AUTOSAR XML (schema 4-0-3)
package /ComponentTypes
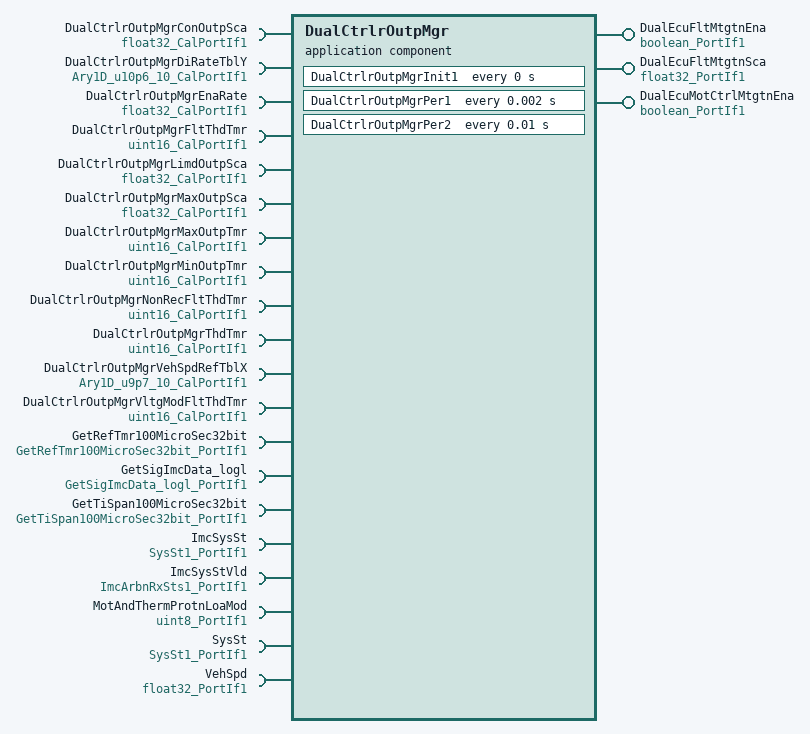
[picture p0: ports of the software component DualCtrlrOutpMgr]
  application sw component type DualCtrlrOutpMgr
    provide port DualEcuFltMtgtnEna: nonqueued-sender-com-spec{data-element=Logl, init-value=0}, provided-interface=boolean_PortIf1
    provide port DualEcuFltMtgtnSca: nonqueued-sender-com-spec{data-element=Val, init-value=0.5}, provided-interface=float32_PortIf1
    provide port DualEcuMotCtrlMtgtnEna: nonqueued-sender-com-spec{data-element=Logl, init-value=0}, provided-interface=boolean_PortIf1
    20 x require port:
      DualCtrlrOutpMgrConOutpSca: parameter-require-com-spec{init-value=0.5, parameter=Val}, required-interface=float32_CalPortIf1
      DualCtrlrOutpMgrDiRateTblY: parameter-require-com-spec{init-value=10 x 6400, parameter=Ary1D}, required-interface=Ary1D_u10p6_10_CalPortIf1
      DualCtrlrOutpMgrEnaRate: parameter-require-com-spec{init-value=100, parameter=Val}, required-interface=float32_CalPortIf1
      DualCtrlrOutpMgrFltThdTmr: parameter-require-com-spec{init-value=20, parameter=Val}, required-interface=uint16_CalPortIf1
      DualCtrlrOutpMgrLimdOutpSca: parameter-require-com-spec{init-value=0.3, parameter=Val}, required-interface=float32_CalPortIf1
      DualCtrlrOutpMgrMaxOutpSca: parameter-require-com-spec{init-value=1, parameter=Val}, required-interface=float32_CalPortIf1
      DualCtrlrOutpMgrMaxOutpTmr: parameter-require-com-spec{init-value=100, parameter=Val}, required-interface=uint16_CalPortIf1
      DualCtrlrOutpMgrMinOutpTmr: parameter-require-com-spec{init-value=100, parameter=Val}, required-interface=uint16_CalPortIf1
      DualCtrlrOutpMgrNonRecFltThdTmr: parameter-require-com-spec{init-value=30, parameter=Val}, required-interface=uint16_CalPortIf1
      DualCtrlrOutpMgrThdTmr: parameter-require-com-spec{init-value=20, parameter=Val}, required-interface=uint16_CalPortIf1
      DualCtrlrOutpMgrVehSpdRefTblX: parameter-require-com-spec{init-value=[0, 1920, 5120, 7680, 9600, 12800, 16000, 16640, 17920, 20480], parameter=Ary1D}, required-interface=Ary1D_u9p7_10_CalPortIf1
      DualCtrlrOutpMgrVltgModFltThdTmr: parameter-require-com-spec{init-value=20, parameter=Val}, required-interface=uint16_CalPortIf1
      GetRefTmr100MicroSec32bit: client-com-spec=Oper, required-interface=GetRefTmr100MicroSec32bit_PortIf1
      GetSigImcData_logl: client-com-spec=Oper, required-interface=GetSigImcData_logl_PortIf1
      GetTiSpan100MicroSec32bit: client-com-spec=Oper, required-interface=GetTiSpan100MicroSec32bit_PortIf1
      ImcSysSt: nonqueued-receiver-com-spec{data-element=Val, filter=data-filter-type=ALWAYS, init-value=3}, required-interface=SysSt1_PortIf1
      ImcSysStVld: nonqueued-receiver-com-spec{data-element=Val, filter=data-filter-type=ALWAYS, init-value=0}, required-interface=ImcArbnRxSts1_PortIf1
      MotAndThermProtnLoaMod: nonqueued-receiver-com-spec{data-element=Val, filter=data-filter-type=ALWAYS, init-value=0}, required-interface=uint8_PortIf1
      SysSt: nonqueued-receiver-com-spec{data-element=Val, filter=data-filter-type=ALWAYS, init-value=3}, required-interface=SysSt1_PortIf1
      VehSpd: nonqueued-receiver-com-spec{data-element=Val, filter=data-filter-type=ALWAYS, init-value=0}, required-interface=float32_PortIf1
    behavior DualCtrlrOutpMgr_InternalBehavior
      ar-typed-per-instance-memorys:
        16 x data, all with sw-calibration-access=READ-ONLY:
          FltLrngEnaPrev: type=boolean
          FltRefTiEnaLrng: type=uint32
          FltStsPrev: type=boolean
          LtchImcDualEcuMotCtrlMtgtnEnaPrev: type=boolean
          LtchRefTiEnaLrng: type=uint32
          LtchSysStPrev: type=boolean
          MaxOutpRefTiEna: type=uint32
          MaxOutpTmrCmpl: type=boolean
          NonRecFltEnaPrev: type=boolean
          NonRecFltRefTiEnaLrng: type=uint32
          OutpSca: type=float32
          PrevLtch: type=boolean
          PrevLtchNonRecFlt: type=boolean
          RefTiEnaLrng: type=uint32
          SysStLrngEnaPrev: type=boolean
          SysStRefTiEnaLrng: type=uint32
      timing event DualCtrlrOutpMgrInit1_InitEvent: start-on-event=DualCtrlrOutpMgrInit1, period=0
      timing event TMT_DualCtrlrOutpMgrPer1: start-on-event=DualCtrlrOutpMgrPer1, period=0.002
      timing event TMT_DualCtrlrOutpMgrPer2: start-on-event=DualCtrlrOutpMgrPer2, period=0.01
      explicit-inter-runnable-variables:
        4 x data, all with type=boolean, init-value=0:
          ImcDiagcStsNonRcvrlReqDiFltPrsnt
          ImcDiagcStsNonRcvrlReqDiFltPrsntVld
          ImcDualEcuMotCtrlMtgtnEna
          ImcDualEcuMotCtrlMtgtnEnaVld
      port-api-options:
        enable-take-address=false, indirect-api=false, port=DualCtrlrOutpMgrConOutpSca
        enable-take-address=false, indirect-api=false, port=DualCtrlrOutpMgrDiRateTblY
        enable-take-address=false, indirect-api=false, port=DualCtrlrOutpMgrEnaRate
        enable-take-address=false, indirect-api=false, port=DualCtrlrOutpMgrFltThdTmr
        enable-take-address=false, indirect-api=false, port=DualCtrlrOutpMgrLimdOutpSca
        enable-take-address=false, indirect-api=false, port=DualCtrlrOutpMgrMaxOutpSca
        enable-take-address=false, indirect-api=false, port=DualCtrlrOutpMgrMaxOutpTmr
        enable-take-address=false, indirect-api=false, port=DualCtrlrOutpMgrMinOutpTmr
        enable-take-address=false, indirect-api=false, port=DualCtrlrOutpMgrNonRecFltThdTmr
        enable-take-address=false, indirect-api=false, port=DualCtrlrOutpMgrThdTmr
        enable-take-address=false, indirect-api=false, port=DualCtrlrOutpMgrVehSpdRefTblX
        enable-take-address=false, indirect-api=false, port=DualCtrlrOutpMgrVltgModFltThdTmr
        enable-take-address=false, indirect-api=false, port=DualEcuFltMtgtnEna
        enable-take-address=false, indirect-api=false, port=DualEcuFltMtgtnSca
        enable-take-address=false, indirect-api=false, port=DualEcuMotCtrlMtgtnEna
        enable-take-address=false, indirect-api=false, port=GetRefTmr100MicroSec32bit
        enable-take-address=false, indirect-api=false, port=GetSigImcData_logl
        enable-take-address=false, indirect-api=false, port=GetTiSpan100MicroSec32bit
        enable-take-address=false, indirect-api=false, port=ImcSysSt
        enable-take-address=false, indirect-api=false, port=ImcSysStVld
        enable-take-address=false, indirect-api=false, port=MotAndThermProtnLoaMod
        enable-take-address=false, indirect-api=false, port=SysSt
        enable-take-address=false, indirect-api=false, port=VehSpd
      runnable DualCtrlrOutpMgrInit1
        sync call SC_GetRefTmr100MicroSec32bit_PortIf1_Oper: operation=GetRefTmr100MicroSec32bit.Oper, timeout=0
      runnable DualCtrlrOutpMgrPer1
        data-receive-point-by-arguments:
          5 x access:
            REC_ImcSysSt_Val: accessed-variable=ImcSysSt.Val
            REC_ImcSysStVld_Val: accessed-variable=ImcSysStVld.Val
            REC_MotAndThermProtnLoaMod_Val: accessed-variable=MotAndThermProtnLoaMod.Val
            REC_SysSt_Val: accessed-variable=SysSt.Val
            REC_VehSpd_Val: accessed-variable=VehSpd.Val
        data-send-points:
          access SEND_DualEcuFltMtgtnEna_Logl: accessed-variable=DualEcuFltMtgtnEna.Logl
          access SEND_DualEcuFltMtgtnSca_Val: accessed-variable=DualEcuFltMtgtnSca.Val
          access SEND_DualEcuMotCtrlMtgtnEna_Logl: accessed-variable=DualEcuMotCtrlMtgtnEna.Logl
        read-local-variables:
          4 x access:
            READ_ImcDiagcStsNonRcvrlReqDiFltPrsnt: accessed-variable=ImcDiagcStsNonRcvrlReqDiFltPrsnt
            READ_ImcDiagcStsNonRcvrlReqDiFltPrsntVld: accessed-variable=ImcDiagcStsNonRcvrlReqDiFltPrsntVld
            READ_ImcDualEcuMotCtrlMtgtnEna: accessed-variable=ImcDualEcuMotCtrlMtgtnEna
            READ_ImcDualEcuMotCtrlMtgtnEnaVld: accessed-variable=ImcDualEcuMotCtrlMtgtnEnaVld
        sync call SC_GetRefTmr100MicroSec32bit_PortIf1_Oper: operation=GetRefTmr100MicroSec32bit.Oper, timeout=0
        sync call SC_GetTiSpan100MicroSec32bit_PortIf1_Oper: operation=GetTiSpan100MicroSec32bit.Oper, timeout=0
      runnable DualCtrlrOutpMgrPer2
        sync call SC_GetSigImcData_logl_PortIf1_Oper: operation=GetSigImcData_logl.Oper, timeout=0
        written-local-variables:
          4 x access:
            WRITE_ImcDiagcStsNonRcvrlReqDiFltPrsnt: accessed-variable=ImcDiagcStsNonRcvrlReqDiFltPrsnt
            WRITE_ImcDiagcStsNonRcvrlReqDiFltPrsntVld: accessed-variable=ImcDiagcStsNonRcvrlReqDiFltPrsntVld
            WRITE_ImcDualEcuMotCtrlMtgtnEna: accessed-variable=ImcDualEcuMotCtrlMtgtnEna
            WRITE_ImcDualEcuMotCtrlMtgtnEnaVld: accessed-variable=ImcDualEcuMotCtrlMtgtnEnaVld
  swc implementation DualCtrlrOutpMgr_Implementation: behavior=DualCtrlrOutpMgr_InternalBehavior
    code-descriptors:
      code Default: artifact-descriptors=autosar-engineering-object={short-label=Default, category=SWSRC}
